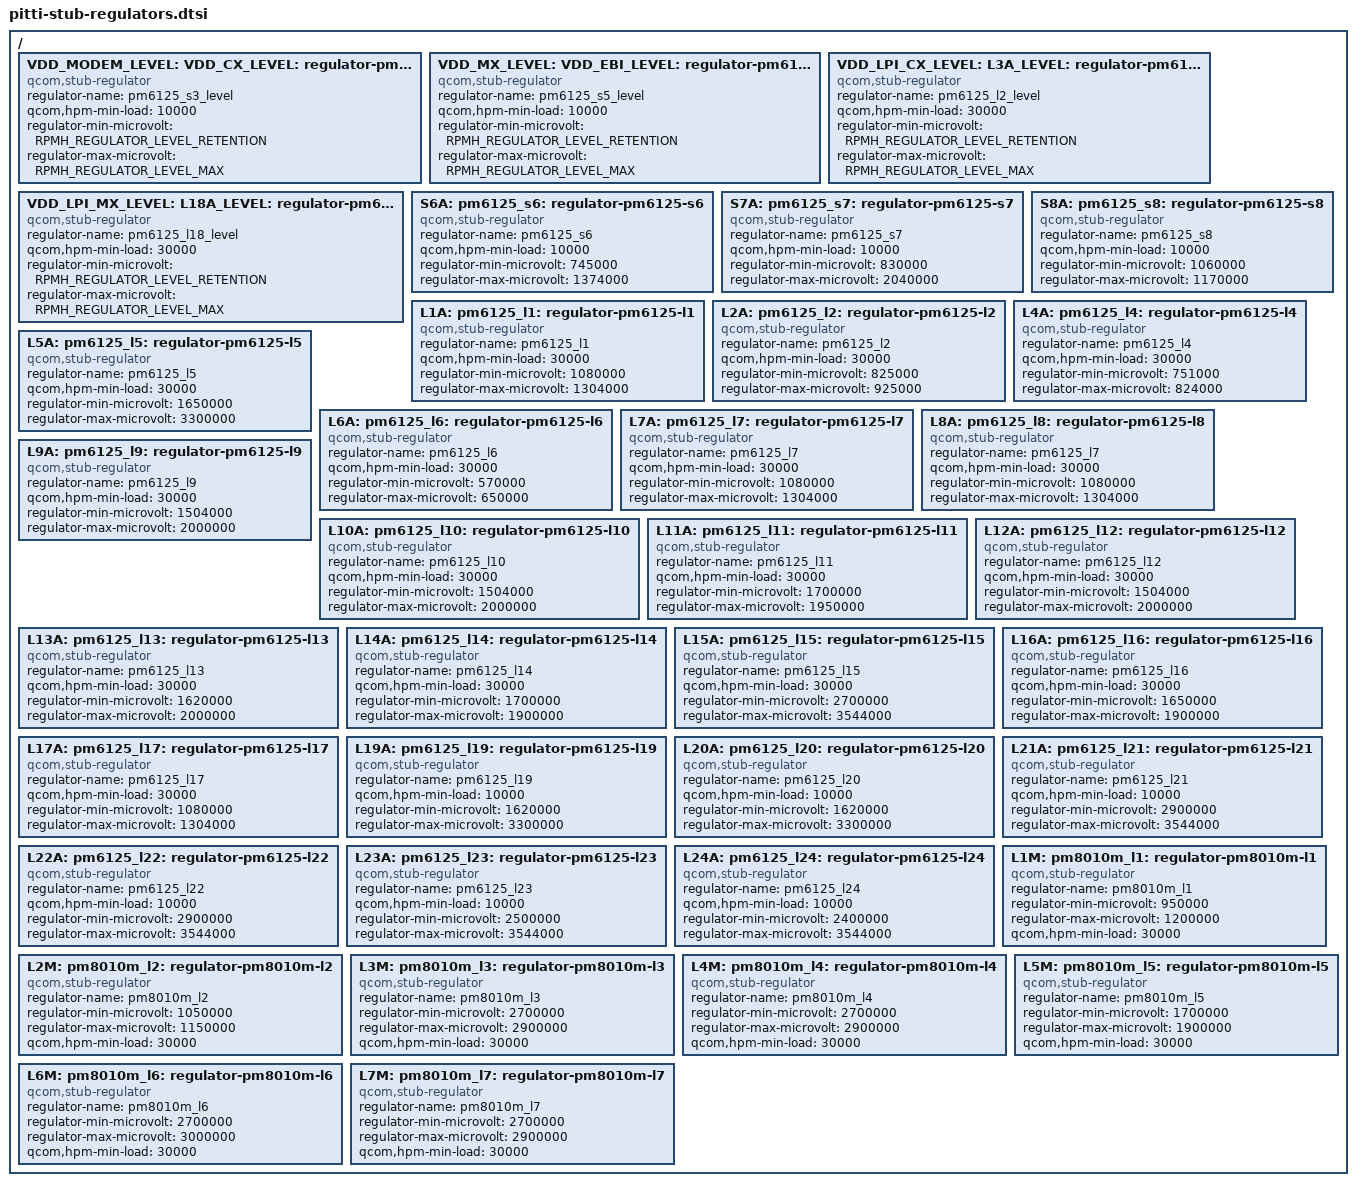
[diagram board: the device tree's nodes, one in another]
#include <dt-bindings/regulator/qcom,rpmh-regulator-levels.h>

/ {
	VDD_MODEM_LEVEL:
	VDD_CX_LEVEL:
	S3A_LEVEL:
	pm6125_s3_level: regulator-pm6125-s3-level {
		compatible = "qcom,stub-regulator";
		regulator-name = "pm6125_s3_level";
		qcom,hpm-min-load = <10000>;
		regulator-min-microvolt =<RPMH_REGULATOR_LEVEL_RETENTION>;
		regulator-max-microvolt = <RPMH_REGULATOR_LEVEL_MAX>;
	};

	VDD_MX_LEVEL:
	VDD_EBI_LEVEL:
	S5A_LEVEL:
	pm6125_s5_level: regulator-pm6125_s5_level {
		compatible = "qcom,stub-regulator";
		regulator-name = "pm6125_s5_level";
		qcom,hpm-min-load = <10000>;
		regulator-min-microvolt = <RPMH_REGULATOR_LEVEL_RETENTION>;
		regulator-max-microvolt = <RPMH_REGULATOR_LEVEL_MAX>;
	};

	VDD_LPI_CX_LEVEL:
	L3A_LEVEL:
	pm6125_l3_level: regulator-pm6125-l3-level {
		compatible = "qcom,stub-regulator";
		regulator-name = "pm6125_l2_level";
		qcom,hpm-min-load = <30000>;
		regulator-min-microvolt = <RPMH_REGULATOR_LEVEL_RETENTION>;
		regulator-max-microvolt = <RPMH_REGULATOR_LEVEL_MAX>;
	};

	VDD_LPI_MX_LEVEL:
	L18A_LEVEL:
	pm6125_l18_level: regulator-pm6125-l18-level {
		compatible = "qcom,stub-regulator";
		regulator-name = "pm6125_l18_level";
		qcom,hpm-min-load = <30000>;
		regulator-min-microvolt =
			<RPMH_REGULATOR_LEVEL_RETENTION>;
		regulator-max-microvolt = <RPMH_REGULATOR_LEVEL_MAX>;
	};

	S6A:
	pm6125_s6: regulator-pm6125-s6 {
		compatible = "qcom,stub-regulator";
		regulator-name = "pm6125_s6";
		qcom,hpm-min-load = <10000>;
		regulator-min-microvolt = <745000>;
		regulator-max-microvolt = <1374000>;
	};

	S7A:
	pm6125_s7: regulator-pm6125-s7 {
		compatible = "qcom,stub-regulator";
		regulator-name = "pm6125_s7";
		qcom,hpm-min-load = <10000>;
		regulator-min-microvolt = <830000>;
		regulator-max-microvolt = <2040000>;
	};

	S8A:
	pm6125_s8: regulator-pm6125-s8 {
		compatible = "qcom,stub-regulator";
		regulator-name = "pm6125_s8";
		qcom,hpm-min-load = <10000>;
		regulator-min-microvolt = <1060000>;
		regulator-max-microvolt = <1170000>;
	};

	L1A:
	pm6125_l1: regulator-pm6125-l1 {
		compatible = "qcom,stub-regulator";
		regulator-name = "pm6125_l1";
		qcom,hpm-min-load = <30000>;
		regulator-min-microvolt = <1080000>;
		regulator-max-microvolt = <1304000>;
	};

	L2A:
	pm6125_l2: regulator-pm6125-l2 {
		compatible = "qcom,stub-regulator";
		regulator-name = "pm6125_l2";
		qcom,hpm-min-load = <30000>;
		regulator-min-microvolt = <825000>;
		regulator-max-microvolt = <925000>;
	};

	L4A:
	pm6125_l4: regulator-pm6125-l4 {
		compatible = "qcom,stub-regulator";
		regulator-name = "pm6125_l4";
		qcom,hpm-min-load = <30000>;
		regulator-min-microvolt = <751000>;
		regulator-max-microvolt = <824000>;
	};

	L5A:
	pm6125_l5: regulator-pm6125-l5 {
		compatible = "qcom,stub-regulator";
		regulator-name = "pm6125_l5";
		qcom,hpm-min-load = <30000>;
		regulator-min-microvolt = <1650000>;
		regulator-max-microvolt = <3300000>;
	};

	L6A:
	pm6125_l6: regulator-pm6125-l6 {
		compatible = "qcom,stub-regulator";
		regulator-name = "pm6125_l6";
		qcom,hpm-min-load = <30000>;
		regulator-min-microvolt = <570000>;
		regulator-max-microvolt = <650000>;
	};

	L7A:
	pm6125_l7: regulator-pm6125-l7 {
		compatible = "qcom,stub-regulator";
		regulator-name = "pm6125_l7";
		qcom,hpm-min-load = <30000>;
		regulator-min-microvolt = <1080000>;
		regulator-max-microvolt = <1304000>;
	};

	L8A:
	pm6125_l8: regulator-pm6125-l8 {
		compatible = "qcom,stub-regulator";
		regulator-name = "pm6125_l7";
		qcom,hpm-min-load = <30000>;
		regulator-min-microvolt = <1080000>;
		regulator-max-microvolt = <1304000>;
	};

	L9A:
	pm6125_l9: regulator-pm6125-l9 {
		compatible = "qcom,stub-regulator";
		regulator-name = "pm6125_l9";
		qcom,hpm-min-load = <30000>;
		regulator-min-microvolt = <1504000>;
		regulator-max-microvolt = <2000000>;
	};

	L10A:
	pm6125_l10: regulator-pm6125-l10 {
		compatible = "qcom,stub-regulator";
		regulator-name = "pm6125_l10";
		qcom,hpm-min-load = <30000>;
		regulator-min-microvolt = <1504000>;
		regulator-max-microvolt = <2000000>;
	};

	L11A:
	pm6125_l11: regulator-pm6125-l11 {
		compatible = "qcom,stub-regulator";
		regulator-name = "pm6125_l11";
		qcom,hpm-min-load = <30000>;
		regulator-min-microvolt = <1700000>;
		regulator-max-microvolt = <1950000>;
	};

	L12A:
	pm6125_l12: regulator-pm6125-l12 {
		compatible = "qcom,stub-regulator";
		regulator-name = "pm6125_l12";
		qcom,hpm-min-load = <30000>;
		regulator-min-microvolt = <1504000>;
		regulator-max-microvolt = <2000000>;
	};

	L13A:
	pm6125_l13: regulator-pm6125-l13 {
		compatible = "qcom,stub-regulator";
		regulator-name = "pm6125_l13";
		qcom,hpm-min-load = <30000>;
		regulator-min-microvolt = <1620000>;
		regulator-max-microvolt = <2000000>;
	};

	L14A:
	pm6125_l14: regulator-pm6125-l14 {
		compatible = "qcom,stub-regulator";
		regulator-name = "pm6125_l14";
		qcom,hpm-min-load = <30000>;
		regulator-min-microvolt = <1700000>;
		regulator-max-microvolt = <1900000>;
	};

	L15A:
	pm6125_l15: regulator-pm6125-l15 {
		compatible = "qcom,stub-regulator";
		regulator-name = "pm6125_l15";
		qcom,hpm-min-load = <30000>;
		regulator-min-microvolt = <2700000>;
		regulator-max-microvolt = <3544000>;
	};

	L16A:
	pm6125_l16: regulator-pm6125-l16 {
		compatible = "qcom,stub-regulator";
		regulator-name = "pm6125_l16";
		qcom,hpm-min-load = <30000>;
		regulator-min-microvolt = <1650000>;
		regulator-max-microvolt = <1900000>;
	};

	L17A:
	pm6125_l17: regulator-pm6125-l17 {
		compatible = "qcom,stub-regulator";
		regulator-name = "pm6125_l17";
		qcom,hpm-min-load = <30000>;
		regulator-min-microvolt = <1080000>;
		regulator-max-microvolt = <1304000>;
	};

	L19A:
	pm6125_l19: regulator-pm6125-l19 {
		compatible = "qcom,stub-regulator";
		regulator-name = "pm6125_l19";
		qcom,hpm-min-load = <10000>;
		regulator-min-microvolt = <1620000>;
		regulator-max-microvolt = <3300000>;
	};

	L20A:
	pm6125_l20: regulator-pm6125-l20 {
		compatible = "qcom,stub-regulator";
		regulator-name = "pm6125_l20";
		qcom,hpm-min-load = <10000>;
		regulator-min-microvolt = <1620000>;
		regulator-max-microvolt = <3300000>;
	};

	L21A:
	pm6125_l21: regulator-pm6125-l21 {
		compatible = "qcom,stub-regulator";
		regulator-name = "pm6125_l21";
		qcom,hpm-min-load = <10000>;
		regulator-min-microvolt = <2900000>;
		regulator-max-microvolt = <3544000>;
	};

	L22A:
	pm6125_l22: regulator-pm6125-l22 {
		compatible = "qcom,stub-regulator";
		regulator-name = "pm6125_l22";
		qcom,hpm-min-load = <10000>;
		regulator-min-microvolt = <2900000>;
		regulator-max-microvolt = <3544000>;
	};

	L23A:
	pm6125_l23: regulator-pm6125-l23 {
		compatible = "qcom,stub-regulator";
		regulator-name = "pm6125_l23";
		qcom,hpm-min-load = <10000>;
		regulator-min-microvolt = <2500000>;
		regulator-max-microvolt = <3544000>;
	};

	L24A:
	pm6125_l24: regulator-pm6125-l24 {
		compatible = "qcom,stub-regulator";
		regulator-name = "pm6125_l24";
		qcom,hpm-min-load = <10000>;
		regulator-min-microvolt = <2400000>;
		regulator-max-microvolt = <3544000>;
	};


	L1M: pm8010m_l1: regulator-pm8010m-l1 {
		compatible = "qcom,stub-regulator";
		regulator-name = "pm8010m_l1";
		regulator-min-microvolt = <950000>;
		regulator-max-microvolt = <1200000>;
		qcom,hpm-min-load = <30000>;
	};

	L2M: pm8010m_l2: regulator-pm8010m-l2 {
		compatible = "qcom,stub-regulator";
		regulator-name = "pm8010m_l2";
		regulator-min-microvolt = <1050000>;
		regulator-max-microvolt = <1150000>;
		qcom,hpm-min-load = <30000>;
	};

	L3M: pm8010m_l3: regulator-pm8010m-l3 {
		compatible = "qcom,stub-regulator";
		regulator-name = "pm8010m_l3";
		regulator-min-microvolt = <2700000>;
		regulator-max-microvolt = <2900000>;
		qcom,hpm-min-load = <30000>;
	};

	L4M: pm8010m_l4: regulator-pm8010m-l4 {
		compatible = "qcom,stub-regulator";
		regulator-name = "pm8010m_l4";
		regulator-min-microvolt = <2700000>;
		regulator-max-microvolt = <2900000>;
		qcom,hpm-min-load = <30000>;
	};

	L5M: pm8010m_l5: regulator-pm8010m-l5 {
		compatible = "qcom,stub-regulator";
		regulator-name = "pm8010m_l5";
		regulator-min-microvolt = <1700000>;
		regulator-max-microvolt = <1900000>;
		qcom,hpm-min-load = <30000>;
	};

	L6M: pm8010m_l6: regulator-pm8010m-l6 {
		compatible = "qcom,stub-regulator";
		regulator-name = "pm8010m_l6";
		regulator-min-microvolt = <2700000>;
		regulator-max-microvolt = <3000000>;
		qcom,hpm-min-load = <30000>;
	};

	L7M: pm8010m_l7: regulator-pm8010m-l7 {
		compatible = "qcom,stub-regulator";
		regulator-name = "pm8010m_l7";
		regulator-min-microvolt = <2700000>;
		regulator-max-microvolt = <2900000>;
		qcom,hpm-min-load = <30000>;
	};
};
